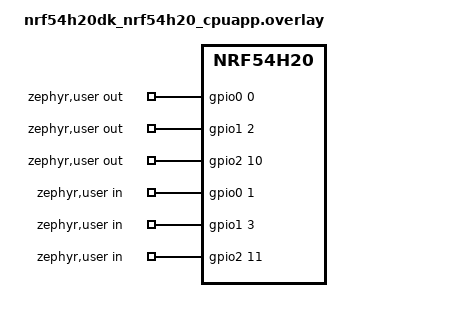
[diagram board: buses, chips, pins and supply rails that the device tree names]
/*
 * Copyright (c) 2026 Nordic Semiconductor ASA
 *
 * SPDX-License-Identifier: LicenseRef-Nordic-5-Clause
 */

/ {
	/* Test requirements:
	 * out-gpios[0] wire connected with in-gpios[0],
	 * out-gpios[1] wire connected with in-gpios[1],
	 * etc.
	 * Output-input GPIO pair must have identical active level flag.
	 */
	zephyr,user {
		out-gpios = <&gpio0 0 GPIO_ACTIVE_HIGH>, <&gpio1 2 GPIO_ACTIVE_HIGH>,
			    <&gpio2 10 GPIO_ACTIVE_HIGH>;
		in-gpios = <&gpio0 1 GPIO_ACTIVE_HIGH>, <&gpio1 3 GPIO_ACTIVE_HIGH>,
			   <&gpio2 11 GPIO_ACTIVE_HIGH>;
	};
};

&gpio0 {
	status = "okay";
};

&gpio1 {
	status = "okay";
};

&gpio2 {
	status = "okay";
};

/* Enable interrupt from GPIO P0, P1, P2, P9 events. */
&gpiote130 {
	status = "okay";
};
